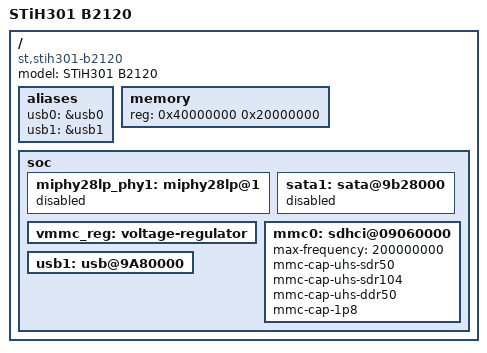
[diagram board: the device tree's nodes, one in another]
/*
 * Copyright (C) 2015 STMicroelectronics (R&D) Limited.
 * Author: Krishna R DHARASURKAR <krishna.dharasurkar@st.com>
 *
 * This program is free software; you can redistribute it and/or modify
 * it under the terms of the GNU General Public License version 2 as
 * published by the Free Software Foundation.
 */
/dts-v1/;
#include "stih301.dtsi"
#include "stihxxx-b2120.dtsi"
/ {
	model = "STiH301 B2120";
	compatible = "st,stih301-b2120", "st,stih301", "st,stih410";

	aliases {
		usb0 = &usb0;
		usb1 = &usb1;
	};

	memory {
		device_type = "memory";
		reg = <0x40000000 0x20000000>;
	};

	soc {
		miphy28lp_phy1: miphy28lp@1 {
			status = "disabled";
		};

		sata1: sata@9b28000 {
			status = "disabled";
		};

		vmmc_reg: voltage-regulator {
			status = "okay";
		};

		mmc0: sdhci@09060000 {
			max-frequency = <200000000>;
			mmc-cap-uhs-sdr50;
			mmc-cap-uhs-sdr104;
			mmc-cap-uhs-ddr50;
			mmc-cap-1p8;
		};

		usb1: usb@9A80000 {
			status = "okay";
		};
	};
};
